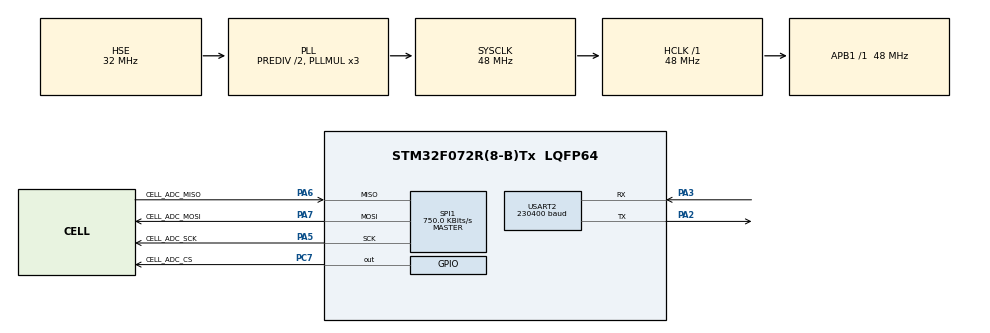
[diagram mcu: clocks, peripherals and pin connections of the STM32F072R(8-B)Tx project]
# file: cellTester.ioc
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Dma.Request0=USART2_RX
Dma.USART2_RX.0.Direction=DMA_PERIPH_TO_MEMORY
Dma.USART2_RX.0.Instance=DMA1_Channel5
Dma.USART2_RX.0.MemDataAlignment=DMA_MDATAALIGN_BYTE
Dma.USART2_RX.0.MemInc=DMA_MINC_ENABLE
Dma.USART2_RX.0.Mode=DMA_CIRCULAR
Dma.USART2_RX.0.PeriphDataAlignment=DMA_PDATAALIGN_BYTE
Dma.USART2_RX.0.PeriphInc=DMA_PINC_DISABLE
Dma.USART2_RX.0.Priority=DMA_PRIORITY_LOW
FREERTOS.INCLUDE_vTaskDelayUntil=1
FREERTOS.Tasks01=mainTask,2,512,mainTaskFunction,As weak,NULL,Dynamic,NULL,NULL;printTaskName,-2,128,printTask,As external,NULL,Dynamic,NULL,NULL;watchDogTaskNam,3,160,watchdogTask,As external,NULL,Dynamic,NULL,NULL
FREERTOS.configCHECK_FOR_STACK_OVERFLOW=2
FREERTOS.configGENERATE_RUN_TIME_STATS=1
FREERTOS.configMINIMAL_STACK_SIZE=64
FREERTOS.configTOTAL_HEAP_SIZE=10000
FREERTOS.configUSE_STATS_FORMATTING_FUNCTIONS=1
FREERTOS.configUSE_TIMERS=1
FREERTOS.configUSE_TRACE_FACILITY=1
IWDG.Reload=400
Mcu.Family=STM32F0
Mcu.Name=STM32F072R(8-B)Tx
Mcu.Package=LQFP64
NVIC.DMA1_Channel4_5_6_7_IRQn=true\:3\:0\:false\:false\:true\:true\:false\:true\:true
NVIC.USART2_IRQn=true\:3\:0\:false\:false\:true\:true\:true\:true\:true
PA2.Mode=Asynchronous
PA2.Signal=USART2_TX
PA3.Mode=Asynchronous
PA3.Signal=USART2_RX
PA5.GPIO_Label=CELL_ADC_SCK
PA5.GPIO_Speed=GPIO_SPEED_FREQ_HIGH
PA5.Mode=Full_Duplex_Master
PA5.Signal=SPI1_SCK
PA6.GPIO_Label=CELL_ADC_MISO
PA6.Mode=Full_Duplex_Master
PA6.Signal=SPI1_MISO
PA7.GPIO_Label=CELL_ADC_MOSI
PA7.Mode=Full_Duplex_Master
PA7.Signal=SPI1_MOSI
PC7.GPIO_Label=CELL_ADC_CS
PC7.GPIO_ModeDefaultOutputPP=GPIO_MODE_OUTPUT_PP
PC7.GPIO_PuPd=GPIO_PULLUP
PC7.GPIO_Speed=GPIO_SPEED_FREQ_HIGH
PC7.PinState=GPIO_PIN_SET
PC7.Signal=GPIO_Output
PF0-OSC_IN.Mode=HSE-External-Oscillator
PF0-OSC_IN.Signal=RCC_OSC_IN
PF1-OSC_OUT.Mode=HSE-External-Oscillator
PF1-OSC_OUT.Signal=RCC_OSC_OUT
ProjectManager.HeapSize=0x200
ProjectManager.StackSize=0x400
ProjectManager.TargetToolchain=STM32CubeIDE
RCC.AHBFreq_Value=48000000
RCC.APB1Freq_Value=48000000
RCC.APB1TimFreq_Value=48000000
RCC.HCLKFreq_Value=48000000
RCC.HSE_VALUE=32000000
RCC.PLLDivider=RCC_PREDIV_DIV2
RCC.PLLMUL=RCC_PLL_MUL3
RCC.PLLSourceVirtual=RCC_PLLSOURCE_HSE
RCC.SYSCLKFreq_VALUE=48000000
RCC.SYSCLKSource=RCC_SYSCLKSOURCE_PLLCLK
SPI1.BaudRatePrescaler=SPI_BAUDRATEPRESCALER_64
SPI1.CLKPhase=SPI_PHASE_2EDGE
SPI1.CLKPolarity=SPI_POLARITY_HIGH
SPI1.CalculateBaudRate=750.0 KBits/s
SPI1.DataSize=SPI_DATASIZE_8BIT
SPI1.Direction=SPI_DIRECTION_2LINES
SPI1.Mode=SPI_MODE_MASTER
SPI1.VirtualType=VM_MASTER
USART2.BaudRate=230400
USART2.VirtualMode-Asynchronous=VM_ASYNC
VP_FREERTOS_VS_CMSIS_V1.Mode=CMSIS_V1
VP_IWDG_VS_IWDG.Mode=IWDG_Activate
VP_TIM2_VS_ClockSourceINT.Mode=Internal
board=custom

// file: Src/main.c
/* USER CODE BEGIN Header */
/**
  ******************************************************************************
  * @file           : main.c
  * @brief          : Main program body
  ******************************************************************************
  * @attention
  *
  * Copyright (c) 2023 STMicroelectronics.
  * All rights reserved.
  *
  * This software is licensed under terms that can be found in the LICENSE file
  * in the root directory of this software component.
  * If no LICENSE file comes with this software, it is provided AS-IS.
  *
  ******************************************************************************
  */
/* USER CODE END Header */
#include "main.h"
#include "cmsis_os.h"
#include "dma.h"
#include "iwdg.h"
#include "spi.h"
#include "tim.h"
#include "usart.h"
#include "gpio.h"

void SystemClock_Config(void);
void MX_FREERTOS_Init(void);
/* USER CODE BEGIN PFP */
__weak void userInit() {}
/* USER CODE END PFP */

int main(void)
{

  /* MCU Configuration--------------------------------------------------------*/

  /* Reset of all peripherals, Initializes the Flash interface and the Systick. */
  HAL_Init();

  /* Configure the system clock */
  SystemClock_Config();

  /* Initialize all configured peripherals */
  MX_GPIO_Init();
  MX_DMA_Init();
  MX_USART2_UART_Init();
  MX_TIM2_Init();
  MX_IWDG_Init();
  MX_SPI1_Init();
  /* USER CODE BEGIN 2 */
  userInit();
  /* USER CODE END 2 */

  /* Call init function for freertos objects (in freertos.c) */
  MX_FREERTOS_Init();

  /* Start scheduler */
  osKernelStart();

  /* We should never get here as control is now taken by the scheduler */
  /* Infinite loop */
  while (1)
  {

  }
}

void SystemClock_Config(void)
{
  RCC_OscInitTypeDef RCC_OscInitStruct = {0};
  RCC_ClkInitTypeDef RCC_ClkInitStruct = {0};
  RCC_PeriphCLKInitTypeDef PeriphClkInit = {0};

  /** Initializes the RCC Oscillators according to the specified parameters
  * in the RCC_OscInitTypeDef structure.
  */
  RCC_OscInitStruct.OscillatorType = RCC_OSCILLATORTYPE_LSI|RCC_OSCILLATORTYPE_HSE;
  RCC_OscInitStruct.HSEState = RCC_HSE_ON;
  RCC_OscInitStruct.LSIState = RCC_LSI_ON;
  RCC_OscInitStruct.PLL.PLLState = RCC_PLL_ON;
  RCC_OscInitStruct.PLL.PLLSource = RCC_PLLSOURCE_HSE;
  RCC_OscInitStruct.PLL.PLLMUL = RCC_PLL_MUL3;
  RCC_OscInitStruct.PLL.PREDIV = RCC_PREDIV_DIV2;
  if (HAL_RCC_OscConfig(&RCC_OscInitStruct) != HAL_OK)
  {
    Error_Handler();
  }

  /** Initializes the CPU, AHB and APB buses clocks
  */
  RCC_ClkInitStruct.ClockType = RCC_CLOCKTYPE_HCLK|RCC_CLOCKTYPE_SYSCLK
                              |RCC_CLOCKTYPE_PCLK1;
  RCC_ClkInitStruct.SYSCLKSource = RCC_SYSCLKSOURCE_PLLCLK;
  RCC_ClkInitStruct.AHBCLKDivider = RCC_SYSCLK_DIV1;
  RCC_ClkInitStruct.APB1CLKDivider = RCC_HCLK_DIV1;

  if (HAL_RCC_ClockConfig(&RCC_ClkInitStruct, FLASH_LATENCY_1) != HAL_OK)
  {
    Error_Handler();
  }
  PeriphClkInit.PeriphClockSelection = RCC_PERIPHCLK_USART2;
  PeriphClkInit.Usart2ClockSelection = RCC_USART2CLKSOURCE_PCLK1;
  if (HAL_RCCEx_PeriphCLKConfig(&PeriphClkInit) != HAL_OK)
  {
    Error_Handler();
  }
}

void Error_Handler(void)
{
  __disable_irq();
  while (1)
  {
  }
}
